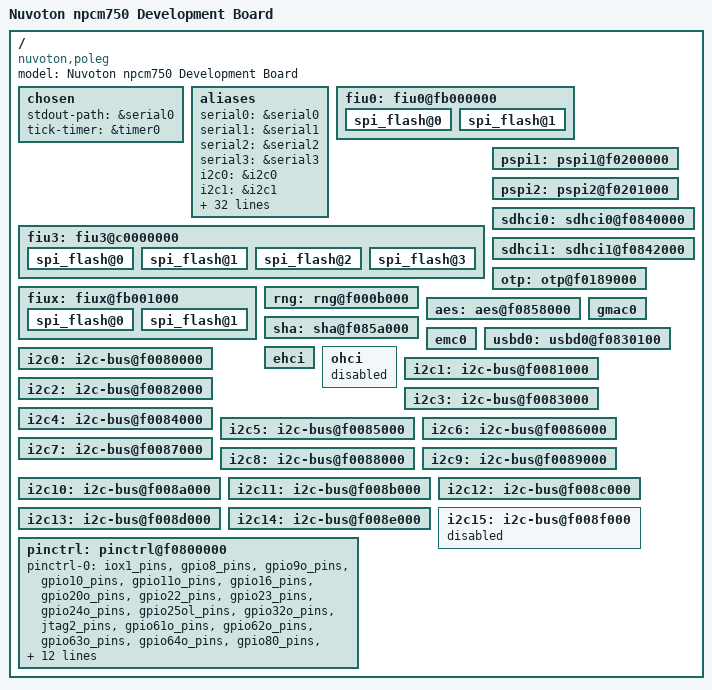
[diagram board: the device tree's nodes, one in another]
/dts-v1/;
#include "nuvoton-common-npcm7xx.dtsi"
#include "nuvoton-npcm750-evb-pincfg.dtsi"

/ {
	model = "Nuvoton npcm750 Development Board";
	compatible = "nuvoton,poleg", "nuvoton,npcm750";

	chosen {
		stdout-path = &serial0;
		tick-timer = &timer0;
	};

	aliases {
		serial0 = &serial0;
		serial1 = &serial1;
		serial2 = &serial2;
		serial3 = &serial3;
		i2c0 = &i2c0;
		i2c1 = &i2c1;
		i2c2 = &i2c2;
		i2c3 = &i2c3;
		i2c4 = &i2c4;
		i2c5 = &i2c5;
		i2c6 = &i2c6;
		i2c7 = &i2c7;
		i2c8 = &i2c8;
		i2c9 = &i2c9;
		i2c10 = &i2c10;
		i2c11 = &i2c11;
		i2c12 = &i2c12;
		i2c13 = &i2c13;
		i2c14 = &i2c14;
		i2c15 = &i2c15;
		spi0 = &fiu0;
		spi3 = &fiu3;
		spi4 = &fiux;
		spi5 = &pspi1;
		spi6 = &pspi2;
		mmc0 = &sdhci0;
		mmc1 = &sdhci1;
		gpio0 = &gpio0;
		gpio1 = &gpio1;
		gpio2 = &gpio2;
		gpio3 = &gpio3;
		gpio4 = &gpio4;
		gpio5 = &gpio5;
		gpio6 = &gpio6;
		gpio7 = &gpio7;
		usb0 = &usbd0;
		eth0 = &emc0;
		eth1 = &gmac0;
	};

	fiu0: fiu0@fb000000 {
		status = "okay";
		spi_flash@0 {
			status = "okay";
		};
		spi_flash@1 {
			status = "okay";
		};
	};

	fiu3: fiu3@c0000000 {
		status = "okay";
		spi_flash@0 {
			status = "okay";
		};
		spi_flash@1 {
			status = "okay";
		};
		spi_flash@2 {
			status = "okay";
		};
		spi_flash@3 {
			status = "okay";
		};
	};

	fiux: fiux@fb001000 {
		status = "okay";
		spi_flash@0 {
			status = "okay";
		};
		spi_flash@1 {
			status = "okay";
		};	
	};
	
	pspi1: pspi1@f0200000 {
		status = "okay";
	};

	pspi2: pspi2@f0201000 {
		status = "okay";
	};

	sdhci0: sdhci0@f0840000 {
		status = "okay";
	};

	sdhci1: sdhci1@f0842000 {
		status = "okay";
	};

	otp: otp@f0189000 {
		status = "okay";
	};

	rng: rng@f000b000 {
		status = "okay";
	};

	aes: aes@f0858000 {
		status = "okay";
	};

	sha: sha@f085a000 {
		status = "okay";
	};

	gmac0: gmac0 {
		status = "okay";
	};

	emc0: emc0 {
		status = "okay";
	};

	usbd0: usbd0@f0830100 {
		status = "okay";
	};

	ehci: ehci {
		status = "okay";
	};

	ohci: ohci {
		status = "disabled";
	};

	i2c0: i2c-bus@f0080000 {
		status = "okay";
	};

	i2c1: i2c-bus@f0081000 {
		status = "okay";
	};

	i2c2: i2c-bus@f0082000 {
		status = "okay";
	};

	i2c3: i2c-bus@f0083000 {
		status = "okay";
	};

	i2c4: i2c-bus@f0084000 {
		status = "okay";
	};

	i2c5: i2c-bus@f0085000 {
		status = "okay";
	};

	i2c6: i2c-bus@f0086000 {
		status = "okay";
	};

	i2c7: i2c-bus@f0087000 {
		status = "okay";
	};

	i2c8: i2c-bus@f0088000 {
		status = "okay";
	};

	i2c9: i2c-bus@f0089000 {
		status = "okay";
	};

	i2c10: i2c-bus@f008a000 {
		status = "okay";
	};

	i2c11: i2c-bus@f008b000 {
		status = "okay";
	};

	i2c12: i2c-bus@f008c000 {
		status = "okay";
	};

	i2c13: i2c-bus@f008d000 {
		status = "okay";
	};

	i2c14: i2c-bus@f008e000 {
		status = "okay";
	};

	i2c15: i2c-bus@f008f000 {
		status = "disabled";  /* conflict with pspi2 cs */
	};
	
	pinctrl: pinctrl@f0800000 {
		pinctrl-names = "default";
		pinctrl-0 = <	&iox1_pins
				&gpio8_pins
				&gpio9o_pins
				&gpio10_pins
				&gpio11o_pins
				&gpio16_pins
				&gpio20o_pins
				&gpio22_pins
				&gpio23_pins
				&gpio24o_pins
				&gpio25ol_pins
				&gpio32o_pins
				&jtag2_pins
				&gpio61o_pins
				&gpio62o_pins
				&gpio63o_pins
				&gpio64o_pins      /* SVB pspi1 enable */
				&gpio80_pins
				&gpio81_pins
				&gpio82_pins
				&gpio83_pins
				&lpc_pins
				&gpio130_pins				
				&gpio131_pins				
				&gpio132_pins
				&gpio133_pins
				&gpio144_pins
				&gpio145_pins
				&gpio146_pins
				&gpio147_pins
				&gpio160_pins
				&gpio162_pins
				&gpio168_pins
				&gpio169_pins
				&gpio170_pins
				&gpio187o_pins
				&gpio190_pins
				&gpio191o_pins
				&gpio192o_pins
				&gpio197ol_pins
				&gpio203o_pins				
				&ddc_pins
				&gpio218_pins
				&gpio219ol_pins
				&gpio220ol_pins
				&gpio221o_pins
				&gpio222_pins
				&gpio223ol_pins
				&spix_pins
				&gpio228ol_pins
				&gpio231o_pins
				&gpio255_pins>;
	};
};
